AUTOSAR XML (schema 00046)
package /ComponentTypes
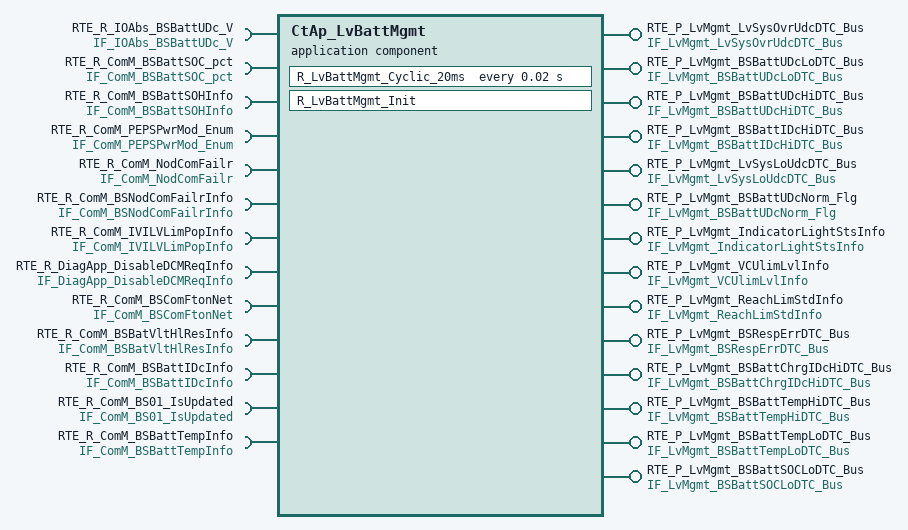
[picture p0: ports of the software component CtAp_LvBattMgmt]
  application sw component type CtAp_LvBattMgmt
    6 x provide port:
      RTE_P_LvMgmt_LvSysOvrUdcDTC_Bus: nonqueued-sender-com-spec{data-element=tec_LvMgmt_LvSysOvrUdcDTC_Bus, init-value=fields=[LvMgmt_MonStatLvSysOvrUDcDTC:0, LvMgmt_MonResLvSysOvrUDcDTC:0, LvMgmt_ErrStatLvSysOvrUDcDTC:0, LvMgmt_ErrResLvSysOvrUDcDTC:0]}, provided-interface=IF_LvMgmt_LvSysOvrUdcDTC_Bus
      RTE_P_LvMgmt_BSBattUDcLoDTC_Bus: nonqueued-sender-com-spec{data-element=tec_LvMgmt_BSBattUDcLoDTC_Bus, init-value=fields=[LvMgmt_MonStatBSBattUDcLoDTC:0, LvMgmt_MonResBSBattUDcLoDTC:0, LvMgmt_ErrStatBSBattUDcLoDTC:0, LvMgmt_ErrResBSBattUDcLoDTC:0]}, provided-interface=IF_LvMgmt_BSBattUDcLoDTC_Bus
      RTE_P_LvMgmt_BSBattUDcHiDTC_Bus: nonqueued-sender-com-spec{data-element=tec_LvMgmt_BSBattUDcHiDTC_Bus, init-value=fields=[LvMgmt_MonStatBSBattUDcHiDTC:0, LvMgmt_MonResBSBattUDcHiDTC:0, LvMgmt_ErrStatBSBattUDcHiDTC:0, LvMgmt_ErrResBSBattUDcHiDTC:0]}, provided-interface=IF_LvMgmt_BSBattUDcHiDTC_Bus
      RTE_P_LvMgmt_BSBattIDcHiDTC_Bus: nonqueued-sender-com-spec{data-element=tec_LvMgmt_BSBattIDcHiDTC_Bus, init-value=fields=[LvMgmt_MonStatBSBattIDcHiDTC:0, LvMgmt_MonResBSBattIDcHiDTC:0, LvMgmt_ErrStatBSBattIDcHiDTC:0, LvMgmt_ErrResBSBattIDcHiDTC:0]}, provided-interface=IF_LvMgmt_BSBattIDcHiDTC_Bus
      RTE_P_LvMgmt_LvSysLoUdcDTC_Bus: nonqueued-sender-com-spec{data-element=tec_LvMgmt_LvSysLoUdcDTC_Bus, init-value=fields=[LvMgmt_MonStatLvSysLoUDcDTC:0, LvMgmt_MonResLvSysLoUDcDTC:0, LvMgmt_ErrStatLvSysLoUDcDTC:0, LvMgmt_ErrResLvSysLoUDcDTC:0]}, provided-interface=IF_LvMgmt_LvSysLoUdcDTC_Bus
      RTE_P_LvMgmt_BSBattUDcNorm_Flg: nonqueued-sender-com-spec{data-element=tec_LvMgmt_BSBattUDcNorm_Flg, init-value=0}, provided-interface=IF_LvMgmt_BSBattUDcNorm_Flg
    6 x require port:
      RTE_R_IOAbs_BSBattUDc_V: nonqueued-receiver-com-spec{data-element=tec_IOAbs_BSBattUDc_V, filter=data-filter-type=ALWAYS, init-value=0}, required-interface=IF_IOAbs_BSBattUDc_V
      RTE_R_ComM_BSBattSOC_pct: nonqueued-receiver-com-spec{data-element=tec_ComM_BSBattSOC_pct, filter=data-filter-type=ALWAYS, init-value=0}, required-interface=IF_ComM_BSBattSOC_pct
      RTE_R_ComM_BSBattSOHInfo: nonqueued-receiver-com-spec{data-element=tec_ComM_BSBattSOHInfo, filter=data-filter-type=ALWAYS, init-value=0}, required-interface=IF_ComM_BSBattSOHInfo
      RTE_R_ComM_PEPSPwrMod_Enum: nonqueued-receiver-com-spec{data-element=tec_ComM_PEPSPwrMod_Enum, filter=data-filter-type=ALWAYS, init-value=0}, required-interface=IF_ComM_PEPSPwrMod_Enum
      RTE_R_ComM_NodComFailr: required-interface=IF_ComM_NodComFailr
        required-com-specs:
          data-element=tec_ComM_APTCNodComFailr_Flg, filter=data-filter-type=ALWAYS, init-value=0
          data-element=tec_ComM_ADCUNodComFailr_Flg, filter=data-filter-type=ALWAYS, init-value=0
          data-element=tec_ComM_ACUNodComFailr_Flg, filter=data-filter-type=ALWAYS, init-value=0
          data-element=tec_ComM_SGWNodComFailr_Flg, filter=data-filter-type=ALWAYS, init-value=0
          data-element=tec_ComM_CGWNodComFailr_Flg, filter=data-filter-type=ALWAYS, init-value=0
          data-element=tec_ComM_TCUNodComFailr_Flg, filter=data-filter-type=ALWAYS, init-value=0
          data-element=tec_ComM_BCMNodComFailr_Flg, filter=data-filter-type=ALWAYS, init-value=0
          data-element=tec_ComM_PRNDNodComFailr_Flg, filter=data-filter-type=ALWAYS, init-value=0
          data-element=tec_ComM_IVINodComFailr_Flg, filter=data-filter-type=ALWAYS, init-value=0
          data-element=tec_ComM_DCDCNodComFailr_Flg, filter=data-filter-type=ALWAYS, init-value=0
          data-element=tec_ComM_OBCNodComFailr_Flg, filter=data-filter-type=ALWAYS, init-value=0
          data-element=tec_ComM_CHIBSNodComFailr_Flg, filter=data-filter-type=ALWAYS, init-value=0
          data-element=tec_ComM_MCUNodComFailr_Flg, filter=data-filter-type=ALWAYS, init-value=0
          data-element=tec_ComM_EVCOMNodComFailr_Flg, filter=data-filter-type=ALWAYS, init-value=0
          data-element=tec_ComM_EPTIBSNodComFailr_Flg, filter=data-filter-type=ALWAYS, init-value=0
          data-element=tec_ComM_DCMNodComFailr_Flg, filter=data-filter-type=ALWAYS, init-value=0
          data-element=tec_ComM_BMSNodComFailr_Flg, filter=data-filter-type=ALWAYS, init-value=0
          data-element=tec_ComM_DCMRRNodComFailr_Flg, filter=data-filter-type=ALWAYS, init-value=0
          data-element=tec_ComM_DCMRLNodComFailr_Flg, filter=data-filter-type=ALWAYS, init-value=0
          data-element=tec_ComM_DCMFRNodComFailr_Flg, filter=data-filter-type=ALWAYS, init-value=0
          data-element=tec_ComM_DCMFLNodComFailr_Flg, filter=data-filter-type=ALWAYS, init-value=0
          data-element=tec_ComM_SGWCHNodComFailr_Flg, filter=data-filter-type=ALWAYS, init-value=0
      RTE_R_ComM_BSNodComFailrInfo: nonqueued-receiver-com-spec{data-element=tec_ComM_BSNodComFailrInfo, filter=data-filter-type=ALWAYS, init-value=0}, required-interface=IF_ComM_BSNodComFailrInfo
    provide port RTE_P_LvMgmt_IndicatorLightStsInfo: nonqueued-sender-com-spec{data-element=tec_LvMgmt_IndicatorLightStsInfo, init-value=0}, provided-interface=IF_LvMgmt_IndicatorLightStsInfo
    provide port RTE_P_LvMgmt_VCUlimLvlInfo: nonqueued-sender-com-spec{data-element=tec_LvMgmt_VCUlimLvlInfo, init-value=0}, provided-interface=IF_LvMgmt_VCUlimLvlInfo
    provide port RTE_P_LvMgmt_ReachLimStdInfo: nonqueued-sender-com-spec{data-element=tec_LvMgmt_ReachLimStdInfo, init-value=0}, provided-interface=IF_LvMgmt_ReachLimStdInfo
    require port RTE_R_ComM_IVILVLimPopInfo: nonqueued-receiver-com-spec{data-element=tec_ComM_IVILVLimPopInfo, filter=data-filter-type=ALWAYS, init-value=0}, required-interface=IF_ComM_IVILVLimPopInfo
    require port RTE_R_DiagApp_DisableDCMReqInfo: nonqueued-receiver-com-spec{data-element=tec_DiagApp_DisableDCMReqInfo, filter=data-filter-type=ALWAYS, init-value=0}, required-interface=IF_DiagApp_DisableDCMReqInfo
    require port RTE_R_ComM_BSComFtonNet: nonqueued-receiver-com-spec{data-element=tec_ComM_BSComFtonNet, filter=data-filter-type=ALWAYS, init-value=0}, required-interface=IF_ComM_BSComFtonNet
    5 x provide port:
      RTE_P_LvMgmt_BSRespErrDTC_Bus: nonqueued-sender-com-spec{data-element=tec_LvMgmt_BSRespErrDTC_Bus, init-value=fields=[LvMgmt_MonStatBSRespErrDTC:0, LvMgmt_MonResBSRespErrDTC:0, LvMgmt_ErrStatBSRespErrDTC:0, LvMgmt_ErrResBSRespErrDTC:0]}, provided-interface=IF_LvMgmt_BSRespErrDTC_Bus
      RTE_P_LvMgmt_BSBattChrgIDcHiDTC_Bus: nonqueued-sender-com-spec{data-element=tec_LvMgmt_BSBattChrgIDcHiDTC_Bus, init-value=fields=[LvMgmt_MonStatBSBattChrgIDcHiDTC:0, LvMgmt_MonResBSBattChrgIDcHiDTC:0, LvMgmt_ErrStatBSBattChrgIDcHiDTC:0, LvMgmt_ErrResBSBattChrgIDcHiDTC:0]}, provided-interface=IF_LvMgmt_BSBattChrgIDcHiDTC_Bus
      RTE_P_LvMgmt_BSBattTempHiDTC_Bus: nonqueued-sender-com-spec{data-element=tec_LvMgmt_BSBattTempHiDTC_Bus, init-value=fields=[LvMgmt_MonStatBSBattTempHiDTC:0, LvMgmt_MonResBSBattTempHiDTC:0, LvMgmt_ErrStatBSBattTempHiDTC:0, LvMgmt_ErrResBSBattTempHiDTC:0]}, provided-interface=IF_LvMgmt_BSBattTempHiDTC_Bus
      RTE_P_LvMgmt_BSBattTempLoDTC_Bus: nonqueued-sender-com-spec{data-element=tec_LvMgmt_BSBattTempLoDTC_Bus, init-value=fields=[LvMgmt_MonStatBSBattTempLoDTC:0, LvMgmt_MonResBSBattTempLoDTC:0, LvMgmt_ErrStatBSBattTempLoDTC:0, LvMgmt_ErrResBSBattTempLoDTC:0]}, provided-interface=IF_LvMgmt_BSBattTempLoDTC_Bus
      RTE_P_LvMgmt_BSBattSOCLoDTC_Bus: nonqueued-sender-com-spec{data-element=tec_LvMgmt_BSBattSOCLoDTC_Bus, init-value=fields=[LvMgmt_MonStatBSBattSOCLoDTC:0, LvMgmt_MonResBSBattSOCLoDTC:0, LvMgmt_ErrStatBSBattSOCLoDTC:0, LvMgmt_ErrResBSBattSOCLoDTC:0]}, provided-interface=IF_LvMgmt_BSBattSOCLoDTC_Bus
    4 x require port:
      RTE_R_ComM_BSBatVltHlResInfo: nonqueued-receiver-com-spec{data-element=tec_ComM_BSBatVltHlResInfo, filter=data-filter-type=ALWAYS, init-value=0}, required-interface=IF_ComM_BSBatVltHlResInfo
      RTE_R_ComM_BSBattIDcInfo: nonqueued-receiver-com-spec{data-element=tec_ComM_BSBattIDcInfo, filter=data-filter-type=ALWAYS, init-value=0}, required-interface=IF_ComM_BSBattIDcInfo
      RTE_R_ComM_BS01_IsUpdated: nonqueued-receiver-com-spec{data-element=tec_ComM_BS01_IsUpdated, filter=data-filter-type=ALWAYS, init-value=0}, required-interface=IF_ComM_BS01_IsUpdated
      RTE_R_ComM_BSBattTempInfo: nonqueued-receiver-com-spec{data-element=tec_ComM_BSBattTempInfo, filter=data-filter-type=ALWAYS, init-value=0}, required-interface=IF_ComM_BSBattTempInfo
    behavior CtAp_LvBattMgmt_InternalBehavior
      timing event TMT_R_LvBattMgmt_Cyclic_20ms: start-on-event=R_LvBattMgmt_Cyclic_20ms, period=0.02
      init event CtAp_LvBattMgmt_InitEvent: start-on-event=R_LvBattMgmt_Init
      runnable R_LvBattMgmt_Cyclic_20ms
        data-receive-point-by-arguments:
          14 x access:
            REC_RTE_R_ComM_BSBattSOC_pct_tec_ComM_BSBattSOC_pct: accessed-variable=RTE_R_ComM_BSBattSOC_pct.tec_ComM_BSBattSOC_pct
            REC_RTE_R_IOAbs_BSBattUDc_V_tec_IOAbs_BSBattUDc_V: accessed-variable=RTE_R_IOAbs_BSBattUDc_V.tec_IOAbs_BSBattUDc_V
            REC_RTE_R_ComM_BSBattSOHInfo_tec_ComM_BSBattSOHInfo: accessed-variable=RTE_R_ComM_BSBattSOHInfo.tec_ComM_BSBattSOHInfo
            REC_RTE_R_ComM_BSNodComFailrInfo_tec_ComM_BSNodComFailrInfo: accessed-variable=RTE_R_ComM_BSNodComFailrInfo.tec_ComM_BSNodComFailrInfo
            REC_RTE_R_ComM_NodComFailr_tec_ComM_BCMNodComFailr_Flg: accessed-variable=RTE_R_ComM_NodComFailr.tec_ComM_BCMNodComFailr_Flg
            REC_RTE_R_ComM_NodComFailr_tec_ComM_IVINodComFailr_Flg: accessed-variable=RTE_R_ComM_NodComFailr.tec_ComM_IVINodComFailr_Flg
            REC_RTE_R_ComM_PEPSPwrMod_Enum_tec_ComM_PEPSPwrMod_Enum: accessed-variable=RTE_R_ComM_PEPSPwrMod_Enum.tec_ComM_PEPSPwrMod_Enum
            REC_RTE_R_ComM_IVILVLimPopInfo_tec_ComM_IVILVLimPopInfo: accessed-variable=RTE_R_ComM_IVILVLimPopInfo.tec_ComM_IVILVLimPopInfo
            REC_RTE_R_DiagApp_DisableDCMReqInfo_tec_DiagApp_DisableDCMReqInfo: accessed-variable=RTE_R_DiagApp_DisableDCMReqInfo.tec_DiagApp_DisableDCMReqInfo
            REC_RTE_R_ComM_BSComFtonNet_tec_ComM_BSComFtonNe: accessed-variable=RTE_R_ComM_BSComFtonNet.tec_ComM_BSComFtonNet
            REC_RTE_R_ComM_BS01_IsUpdated_tec_ComM_BS01_IsUpdated: accessed-variable=RTE_R_ComM_BS01_IsUpdated.tec_ComM_BS01_IsUpdated
            REC_RTE_R_ComM_BSBatVltHlResInfo_tec_ComM_BSBatVltHlResInfo: accessed-variable=RTE_R_ComM_BSBatVltHlResInfo.tec_ComM_BSBatVltHlResInfo
            REC_RTE_R_ComM_BSBattIDcInfo_tec_ComM_BSBattIDcInfo: accessed-variable=RTE_R_ComM_BSBattIDcInfo.tec_ComM_BSBattIDcInfo
            REC_RTE_R_ComM_BSBattTempInfo_tec_ComM_BSBattTempInfo: accessed-variable=RTE_R_ComM_BSBattTempInfo.tec_ComM_BSBattTempInfo
        data-send-points:
          14 x access:
            SEND_RTE_P_LvMgmt_BSBattIDcHiDTC_Bus_tec_LvMgmt_BSBattIDcHiDTC_Bus: accessed-variable=RTE_P_LvMgmt_BSBattIDcHiDTC_Bus.tec_LvMgmt_BSBattIDcHiDTC_Bus
            SEND_RTE_P_LvMgmt_BSBattUDcHiDTC_Bus_tec_LvMgmt_BSBattUDcHiDTC_Bus: accessed-variable=RTE_P_LvMgmt_BSBattUDcHiDTC_Bus.tec_LvMgmt_BSBattUDcHiDTC_Bus
            SEND_RTE_P_LvMgmt_BSBattUDcLoDTC_Bus_tec_LvMgmt_BSBattUDcLoDTC_Bus: accessed-variable=RTE_P_LvMgmt_BSBattUDcLoDTC_Bus.tec_LvMgmt_BSBattUDcLoDTC_Bus
            SEND_RTE_P_LvMgmt_BSBattUDcNorm_Flg_tec_LvMgmt_BSBattUDcNorm_Flg: accessed-variable=RTE_P_LvMgmt_BSBattUDcNorm_Flg.tec_LvMgmt_BSBattUDcNorm_Flg
            SEND_RTE_P_LvMgmt_LvSysLoUdcDTC_Bus_tec_LvMgmt_LvSysLoUdcDTC_Bus: accessed-variable=RTE_P_LvMgmt_LvSysLoUdcDTC_Bus.tec_LvMgmt_LvSysLoUdcDTC_Bus
            SEND_RTE_P_LvMgmt_LvSysOvrUdcDTC_Bus_tec_LvMgmt_LvSysOvrUdcDTC_Bus: accessed-variable=RTE_P_LvMgmt_LvSysOvrUdcDTC_Bus.tec_LvMgmt_LvSysOvrUdcDTC_Bus
            SEND_RTE_P_LvMgmt_IndicatorLightStsInfo_tec_LvMgmt_IndicatorLightStsInfo: accessed-variable=RTE_P_LvMgmt_IndicatorLightStsInfo.tec_LvMgmt_IndicatorLightStsInfo
            SEND_RTE_P_LvMgmt_ReachLimStdInfo_tec_LvMgmt_ReachLimStdInfo: accessed-variable=RTE_P_LvMgmt_ReachLimStdInfo.tec_LvMgmt_ReachLimStdInfo
            SEND_RTE_P_LvMgmt_VCUlimLvlInfo_tec_LvMgmt_VCUlimLvlInfo: accessed-variable=RTE_P_LvMgmt_VCUlimLvlInfo.tec_LvMgmt_VCUlimLvlInfo
            SEND_RTE_P_LvMgmt_BSBattChrgIDcHiDTC_Bus_tec_LvMgmt_BSBattChrgIDcHiDTC_Bus: accessed-variable=RTE_P_LvMgmt_BSBattChrgIDcHiDTC_Bus.tec_LvMgmt_BSBattChrgIDcHiDTC_Bus
            SEND_RTE_P_LvMgmt_BSBattSOCLoDTC_Bus_tec_LvMgmt_BSBattSOCLoDTC_Bus: accessed-variable=RTE_P_LvMgmt_BSBattSOCLoDTC_Bus.tec_LvMgmt_BSBattSOCLoDTC_Bus
            SEND_RTE_P_LvMgmt_BSBattTempHiDTC_Bus_tec_LvMgmt_BSBattTempHiDTC_Bus: accessed-variable=RTE_P_LvMgmt_BSBattTempHiDTC_Bus.tec_LvMgmt_BSBattTempHiDTC_Bus
            SEND_RTE_P_LvMgmt_BSBattTempLoDTC_Bus_tec_LvMgmt_BSBattTempLoDTC_Bus: accessed-variable=RTE_P_LvMgmt_BSBattTempLoDTC_Bus.tec_LvMgmt_BSBattTempLoDTC_Bus
            SEND_RTE_P_LvMgmt_BSRespErrDTC_Bus_tec_LvMgmt_BSRespErrDTC_Bus: accessed-variable=RTE_P_LvMgmt_BSRespErrDTC_Bus.tec_LvMgmt_BSRespErrDTC_Bus
      runnable R_LvBattMgmt_Init
  swc implementation CtAp_LvBattMgmt_Implementation: behavior=CtAp_LvBattMgmt_InternalBehavior
